[part 1 of 2: packages /MICROSAR/Dem_swc/DataTypes to /MICROSAR/Dem_swc/ComponentTypes]
AUTOSAR XML (schema 00046)
package /MICROSAR/Dem_swc/DataTypes
  23 x impl type:
    Dem_EventIdType: range raw 1..65535, implementation-data-type=uint16
    Dem_RatioIdType: range raw 1..65535, implementation-data-type=uint16
    Dem_DTCStatusMaskType: range raw 0..255, implementation-data-type=uint8
    Dem_OperationCycleIdType: range raw 0..255, implementation-data-type=uint8
    Dem_DTCGroupType: range raw 0..16777215, implementation-data-type=uint32
    Dem_EventStatusType:
      compu {0=DEM_EVENT_STATUS_PASSED, 1=DEM_EVENT_STATUS_FAILED, 2=DEM_EVENT_STATUS_PREPASSED, 3=DEM_EVENT_STATUS_PREFAILED, 4=DEM_EVENT_STATUS_FDC_THRESHOLD_REACHED, 5=DEM_EVENT_STATUS_PASSED_CONDITIONS_NOT_FULFILLED, 6=DEM_EVENT_STATUS_FAILED_CONDITIONS_NOT_FULFILLED, 7=DEM_EVENT_STATUS_PREPASSED_CONDITIONS_NOT_FULFILLED, 8=DEM_EVENT_STATUS_PREFAILED_CONDITIONS_NOT_FULFILLED}
      range raw 0..255
      implementation-data-type=uint8
    Dem_InitMonitorReasonType: compu {1=DEM_INIT_MONITOR_CLEAR, 2=DEM_INIT_MONITOR_RESTART, 3=DEM_INIT_MONITOR_REENABLED, 4=DEM_INIT_MONITOR_STORAGE_REENABLED}, range raw 0..255, implementation-data-type=uint8
    Dem_DTCOriginType:
      compu {1=DEM_DTC_ORIGIN_PRIMARY_MEMORY, 2=DEM_DTC_ORIGIN_MIRROR_MEMORY, 3=DEM_DTC_ORIGIN_PERMANENT_MEMORY, 4=DEM_DTC_ORIGIN_OBD_RELEVANT_MEMORY, 5=DEM_DTC_ORIGIN_SECONDARY_MEMORY, 5=DEM_DTC_ORIGIN_USERDEFINED_MEMORY_10, 5=DEM_DTC_ORIGIN_USERDEFINED_MEMORY_11, 5=DEM_DTC_ORIGIN_USERDEFINED_MEMORY_12, 5=DEM_DTC_ORIGIN_USERDEFINED_MEMORY_13, 5=DEM_DTC_ORIGIN_USERDEFINED_MEMORY_14, 5=DEM_DTC_ORIGIN_USERDEFINED_MEMORY_15, 5=DEM_DTC_ORIGIN_USERDEFINED_MEMORY_16, 5=DEM_DTC_ORIGIN_USERDEFINED_MEMORY_17, 5=DEM_DTC_ORIGIN_USERDEFINED_MEMORY_18, 5=DEM_DTC_ORIGIN_USERDEFINED_MEMORY_19, 5=DEM_DTC_ORIGIN_USERDEFINED_MEMORY_1A, 5=DEM_DTC_ORIGIN_USERDEFINED_MEMORY_1B, 5=DEM_DTC_ORIGIN_USERDEFINED_MEMORY_1C, 5=DEM_DTC_ORIGIN_USERDEFINED_MEMORY_1D, 5=DEM_DTC_ORIGIN_USERDEFINED_MEMORY_1E, 5=DEM_DTC_ORIGIN_USERDEFINED_MEMORY_1F, 5=DEM_DTC_ORIGIN_USERDEFINED_MEMORY_20, 5=DEM_DTC_ORIGIN_USERDEFINED_MEMORY_21, 5=DEM_DTC_ORIGIN_USERDEFINED_MEMORY_22, 5=DEM_DTC_ORIGIN_USERDEFINED_MEMORY_23, 5=DEM_DTC_ORIGIN_USERDEFINED_MEMORY_24, 5=DEM_DTC_ORIGIN_USERDEFINED_MEMORY_25, 5=DEM_DTC_ORIGIN_USERDEFINED_MEMORY_26, 5=DEM_DTC_ORIGIN_USERDEFINED_MEMORY_27, 5=DEM_DTC_ORIGIN_USERDEFINED_MEMORY_28, 5=DEM_DTC_ORIGIN_USERDEFINED_MEMORY_29, 5=DEM_DTC_ORIGIN_USERDEFINED_MEMORY_2A, 5=DEM_DTC_ORIGIN_USERDEFINED_MEMORY_2B, 5=DEM_DTC_ORIGIN_USERDEFINED_MEMORY_2C, 5=DEM_DTC_ORIGIN_USERDEFINED_MEMORY_2D, 5=DEM_DTC_ORIGIN_USERDEFINED_MEMORY_2E, 5=DEM_DTC_ORIGIN_USERDEFINED_MEMORY_2F, 5=DEM_DTC_ORIGIN_USERDEFINED_MEMORY_30, 5=DEM_DTC_ORIGIN_USERDEFINED_MEMORY_31, 5=DEM_DTC_ORIGIN_USERDEFINED_MEMORY_32, 5=DEM_DTC_ORIGIN_USERDEFINED_MEMORY_33, 5=DEM_DTC_ORIGIN_USERDEFINED_MEMORY_34, 5=DEM_DTC_ORIGIN_USERDEFINED_MEMORY_35, 5=DEM_DTC_ORIGIN_USERDEFINED_MEMORY_36, 5=DEM_DTC_ORIGIN_USERDEFINED_MEMORY_37, 5=DEM_DTC_ORIGIN_USERDEFINED_MEMORY_38, 5=DEM_DTC_ORIGIN_USERDEFINED_MEMORY_39, 5=DEM_DTC_ORIGIN_USERDEFINED_MEMORY_3A, 5=DEM_DTC_ORIGIN_USERDEFINED_MEMORY_3B, 5=DEM_DTC_ORIGIN_USERDEFINED_MEMORY_3C, 5=DEM_DTC_ORIGIN_USERDEFINED_MEMORY_3D, 5=DEM_DTC_ORIGIN_USERDEFINED_MEMORY_3E, 5=DEM_DTC_ORIGIN_USERDEFINED_MEMORY_3F, 5=DEM_DTC_ORIGIN_USERDEFINED_MEMORY_40, 5=DEM_DTC_ORIGIN_USERDEFINED_MEMORY_41, 5=DEM_DTC_ORIGIN_USERDEFINED_MEMORY_42, 5=DEM_DTC_ORIGIN_USERDEFINED_MEMORY_43, 5=DEM_DTC_ORIGIN_USERDEFINED_MEMORY_44, 5=DEM_DTC_ORIGIN_USERDEFINED_MEMORY_45, 5=DEM_DTC_ORIGIN_USERDEFINED_MEMORY_46, 5=DEM_DTC_ORIGIN_USERDEFINED_MEMORY_47, 5=DEM_DTC_ORIGIN_USERDEFINED_MEMORY_48, 5=DEM_DTC_ORIGIN_USERDEFINED_MEMORY_49, 5=DEM_DTC_ORIGIN_USERDEFINED_MEMORY_4A, 5=DEM_DTC_ORIGIN_USERDEFINED_MEMORY_4B, 5=DEM_DTC_ORIGIN_USERDEFINED_MEMORY_4C, 5=DEM_DTC_ORIGIN_USERDEFINED_MEMORY_4D, 5=DEM_DTC_ORIGIN_USERDEFINED_MEMORY_4E, 5=DEM_DTC_ORIGIN_USERDEFINED_MEMORY_4F, 5=DEM_DTC_ORIGIN_USERDEFINED_MEMORY_50, 5=DEM_DTC_ORIGIN_USERDEFINED_MEMORY_51, 5=DEM_DTC_ORIGIN_USERDEFINED_MEMORY_52, 5=DEM_DTC_ORIGIN_USERDEFINED_MEMORY_53, 5=DEM_DTC_ORIGIN_USERDEFINED_MEMORY_54, 5=DEM_DTC_ORIGIN_USERDEFINED_MEMORY_55, 5=DEM_DTC_ORIGIN_USERDEFINED_MEMORY_56, 5=DEM_DTC_ORIGIN_USERDEFINED_MEMORY_57, 5=DEM_DTC_ORIGIN_USERDEFINED_MEMORY_58, 5=DEM_DTC_ORIGIN_USERDEFINED_MEMORY_59, 5=DEM_DTC_ORIGIN_USERDEFINED_MEMORY_5A, 5=DEM_DTC_ORIGIN_USERDEFINED_MEMORY_5B, 5=DEM_DTC_ORIGIN_USERDEFINED_MEMORY_5C, 5=DEM_DTC_ORIGIN_USERDEFINED_MEMORY_5D, 5=DEM_DTC_ORIGIN_USERDEFINED_MEMORY_5E, 5=DEM_DTC_ORIGIN_USERDEFINED_MEMORY_5F, 5=DEM_DTC_ORIGIN_USERDEFINED_MEMORY_60, 5=DEM_DTC_ORIGIN_USERDEFINED_MEMORY_61, 5=DEM_DTC_ORIGIN_USERDEFINED_MEMORY_62, 5=DEM_DTC_ORIGIN_USERDEFINED_MEMORY_63, 5=DEM_DTC_ORIGIN_USERDEFINED_MEMORY_64, 5=DEM_DTC_ORIGIN_USERDEFINED_MEMORY_65, 5=DEM_DTC_ORIGIN_USERDEFINED_MEMORY_66, 5=DEM_DTC_ORIGIN_USERDEFINED_MEMORY_67, 5=DEM_DTC_ORIGIN_USERDEFINED_MEMORY_68, 5=DEM_DTC_ORIGIN_USERDEFINED_MEMORY_69, 5=DEM_DTC_ORIGIN_USERDEFINED_MEMORY_6A, 5=DEM_DTC_ORIGIN_USERDEFINED_MEMORY_6B, 5=DEM_DTC_ORIGIN_USERDEFINED_MEMORY_6C, 5=DEM_DTC_ORIGIN_USERDEFINED_MEMORY_6D, 5=DEM_DTC_ORIGIN_USERDEFINED_MEMORY_6E, 5=DEM_DTC_ORIGIN_USERDEFINED_MEMORY_6F, 5=DEM_DTC_ORIGIN_USERDEFINED_MEMORY_70, 5=DEM_DTC_ORIGIN_USERDEFINED_MEMORY_71, 5=DEM_DTC_ORIGIN_USERDEFINED_MEMORY_72, 5=DEM_DTC_ORIGIN_USERDEFINED_MEMORY_73, 5=DEM_DTC_ORIGIN_USERDEFINED_MEMORY_74, 5=DEM_DTC_ORIGIN_USERDEFINED_MEMORY_75, 5=DEM_DTC_ORIGIN_USERDEFINED_MEMORY_76, 5=DEM_DTC_ORIGIN_USERDEFINED_MEMORY_77, 5=DEM_DTC_ORIGIN_USERDEFINED_MEMORY_78, 5=DEM_DTC_ORIGIN_USERDEFINED_MEMORY_79, 5=DEM_DTC_ORIGIN_USERDEFINED_MEMORY_7A, 5=DEM_DTC_ORIGIN_USERDEFINED_MEMORY_7B, 5=DEM_DTC_ORIGIN_USERDEFINED_MEMORY_7C, 5=DEM_DTC_ORIGIN_USERDEFINED_MEMORY_7D, 5=DEM_DTC_ORIGIN_USERDEFINED_MEMORY_7E, 5=DEM_DTC_ORIGIN_USERDEFINED_MEMORY_7F, 5=DEM_DTC_ORIGIN_USERDEFINED_MEMORY_80, 5=DEM_DTC_ORIGIN_USERDEFINED_MEMORY_81, 5=DEM_DTC_ORIGIN_USERDEFINED_MEMORY_82, 5=DEM_DTC_ORIGIN_USERDEFINED_MEMORY_83, 5=DEM_DTC_ORIGIN_USERDEFINED_MEMORY_84, 5=DEM_DTC_ORIGIN_USERDEFINED_MEMORY_85, 5=DEM_DTC_ORIGIN_USERDEFINED_MEMORY_86, 5=DEM_DTC_ORIGIN_USERDEFINED_MEMORY_87, 5=DEM_DTC_ORIGIN_USERDEFINED_MEMORY_88, 5=DEM_DTC_ORIGIN_USERDEFINED_MEMORY_89, 5=DEM_DTC_ORIGIN_USERDEFINED_MEMORY_8A, 5=DEM_DTC_ORIGIN_USERDEFINED_MEMORY_8B, 5=DEM_DTC_ORIGIN_USERDEFINED_MEMORY_8C, 5=DEM_DTC_ORIGIN_USERDEFINED_MEMORY_8D, 5=DEM_DTC_ORIGIN_USERDEFINED_MEMORY_8E, 5=DEM_DTC_ORIGIN_USERDEFINED_MEMORY_8F, 5=DEM_DTC_ORIGIN_USERDEFINED_MEMORY_90, 5=DEM_DTC_ORIGIN_USERDEFINED_MEMORY_91, 5=DEM_DTC_ORIGIN_USERDEFINED_MEMORY_92, 5=DEM_DTC_ORIGIN_USERDEFINED_MEMORY_93, 5=DEM_DTC_ORIGIN_USERDEFINED_MEMORY_94, 5=DEM_DTC_ORIGIN_USERDEFINED_MEMORY_95, 5=DEM_DTC_ORIGIN_USERDEFINED_MEMORY_96, 5=DEM_DTC_ORIGIN_USERDEFINED_MEMORY_97, 5=DEM_DTC_ORIGIN_USERDEFINED_MEMORY_98, 5=DEM_DTC_ORIGIN_USERDEFINED_MEMORY_99, 5=DEM_DTC_ORIGIN_USERDEFINED_MEMORY_9A, 5=DEM_DTC_ORIGIN_USERDEFINED_MEMORY_9B, 5=DEM_DTC_ORIGIN_USERDEFINED_MEMORY_9C, 5=DEM_DTC_ORIGIN_USERDEFINED_MEMORY_9D, 5=DEM_DTC_ORIGIN_USERDEFINED_MEMORY_9E, 5=DEM_DTC_ORIGIN_USERDEFINED_MEMORY_9F, 5=DEM_DTC_ORIGIN_USERDEFINED_MEMORY_A0, 5=DEM_DTC_ORIGIN_USERDEFINED_MEMORY_A1, 5=DEM_DTC_ORIGIN_USERDEFINED_MEMORY_A2, 5=DEM_DTC_ORIGIN_USERDEFINED_MEMORY_A3, 5=DEM_DTC_ORIGIN_USERDEFINED_MEMORY_A4, 5=DEM_DTC_ORIGIN_USERDEFINED_MEMORY_A5, 5=DEM_DTC_ORIGIN_USERDEFINED_MEMORY_A6, 5=DEM_DTC_ORIGIN_USERDEFINED_MEMORY_A7, 5=DEM_DTC_ORIGIN_USERDEFINED_MEMORY_A8, 5=DEM_DTC_ORIGIN_USERDEFINED_MEMORY_A9, 5=DEM_DTC_ORIGIN_USERDEFINED_MEMORY_AA, 5=DEM_DTC_ORIGIN_USERDEFINED_MEMORY_AB, 5=DEM_DTC_ORIGIN_USERDEFINED_MEMORY_AC, 5=DEM_DTC_ORIGIN_USERDEFINED_MEMORY_AD, 5=DEM_DTC_ORIGIN_USERDEFINED_MEMORY_AE, 5=DEM_DTC_ORIGIN_USERDEFINED_MEMORY_AF, 5=DEM_DTC_ORIGIN_USERDEFINED_MEMORY_B0, 5=DEM_DTC_ORIGIN_USERDEFINED_MEMORY_B1, 5=DEM_DTC_ORIGIN_USERDEFINED_MEMORY_B2, 5=DEM_DTC_ORIGIN_USERDEFINED_MEMORY_B3, 5=DEM_DTC_ORIGIN_USERDEFINED_MEMORY_B4, 5=DEM_DTC_ORIGIN_USERDEFINED_MEMORY_B5, 5=DEM_DTC_ORIGIN_USERDEFINED_MEMORY_B6, 5=DEM_DTC_ORIGIN_USERDEFINED_MEMORY_B7, 5=DEM_DTC_ORIGIN_USERDEFINED_MEMORY_B8, 5=DEM_DTC_ORIGIN_USERDEFINED_MEMORY_B9, 5=DEM_DTC_ORIGIN_USERDEFINED_MEMORY_BA, 5=DEM_DTC_ORIGIN_USERDEFINED_MEMORY_BB, 5=DEM_DTC_ORIGIN_USERDEFINED_MEMORY_BC, 5=DEM_DTC_ORIGIN_USERDEFINED_MEMORY_BD, 5=DEM_DTC_ORIGIN_USERDEFINED_MEMORY_BE, 5=DEM_DTC_ORIGIN_USERDEFINED_MEMORY_BF, 5=DEM_DTC_ORIGIN_USERDEFINED_MEMORY_C0, 5=DEM_DTC_ORIGIN_USERDEFINED_MEMORY_C1, 5=DEM_DTC_ORIGIN_USERDEFINED_MEMORY_C2, 5=DEM_DTC_ORIGIN_USERDEFINED_MEMORY_C3, 5=DEM_DTC_ORIGIN_USERDEFINED_MEMORY_C4, 5=DEM_DTC_ORIGIN_USERDEFINED_MEMORY_C5, 5=DEM_DTC_ORIGIN_USERDEFINED_MEMORY_C6, 5=DEM_DTC_ORIGIN_USERDEFINED_MEMORY_C7, 5=DEM_DTC_ORIGIN_USERDEFINED_MEMORY_C8, 5=DEM_DTC_ORIGIN_USERDEFINED_MEMORY_C9, 5=DEM_DTC_ORIGIN_USERDEFINED_MEMORY_CA, 5=DEM_DTC_ORIGIN_USERDEFINED_MEMORY_CB, 5=DEM_DTC_ORIGIN_USERDEFINED_MEMORY_CC, 5=DEM_DTC_ORIGIN_USERDEFINED_MEMORY_CD, 5=DEM_DTC_ORIGIN_USERDEFINED_MEMORY_CE, 5=DEM_DTC_ORIGIN_USERDEFINED_MEMORY_CF, 5=DEM_DTC_ORIGIN_USERDEFINED_MEMORY_D0, 5=DEM_DTC_ORIGIN_USERDEFINED_MEMORY_D1, 5=DEM_DTC_ORIGIN_USERDEFINED_MEMORY_D2, 5=DEM_DTC_ORIGIN_USERDEFINED_MEMORY_D3, 5=DEM_DTC_ORIGIN_USERDEFINED_MEMORY_D4, 5=DEM_DTC_ORIGIN_USERDEFINED_MEMORY_D5, 5=DEM_DTC_ORIGIN_USERDEFINED_MEMORY_D6, 5=DEM_DTC_ORIGIN_USERDEFINED_MEMORY_D7, 5=DEM_DTC_ORIGIN_USERDEFINED_MEMORY_D8, 5=DEM_DTC_ORIGIN_USERDEFINED_MEMORY_D9, 5=DEM_DTC_ORIGIN_USERDEFINED_MEMORY_DA, 5=DEM_DTC_ORIGIN_USERDEFINED_MEMORY_DB, 5=DEM_DTC_ORIGIN_USERDEFINED_MEMORY_DC, 5=DEM_DTC_ORIGIN_USERDEFINED_MEMORY_DD, 5=DEM_DTC_ORIGIN_USERDEFINED_MEMORY_DE, 5=DEM_DTC_ORIGIN_USERDEFINED_MEMORY_DF, 5=DEM_DTC_ORIGIN_USERDEFINED_MEMORY_E0, 5=DEM_DTC_ORIGIN_USERDEFINED_MEMORY_E1, 5=DEM_DTC_ORIGIN_USERDEFINED_MEMORY_E2, 5=DEM_DTC_ORIGIN_USERDEFINED_MEMORY_E3, 5=DEM_DTC_ORIGIN_USERDEFINED_MEMORY_E4, 5=DEM_DTC_ORIGIN_USERDEFINED_MEMORY_E5, 5=DEM_DTC_ORIGIN_USERDEFINED_MEMORY_E6, 5=DEM_DTC_ORIGIN_USERDEFINED_MEMORY_E7, 5=DEM_DTC_ORIGIN_USERDEFINED_MEMORY_E8, 5=DEM_DTC_ORIGIN_USERDEFINED_MEMORY_E9, 5=DEM_DTC_ORIGIN_USERDEFINED_MEMORY_EA, 5=DEM_DTC_ORIGIN_USERDEFINED_MEMORY_EB, 5=DEM_DTC_ORIGIN_USERDEFINED_MEMORY_EC, 5=DEM_DTC_ORIGIN_USERDEFINED_MEMORY_ED, 5=DEM_DTC_ORIGIN_USERDEFINED_MEMORY_EE, 5=DEM_DTC_ORIGIN_USERDEFINED_MEMORY_EF, 5=DEM_DTC_ORIGIN_USERDEFINED_MEMORY_F0, 5=DEM_DTC_ORIGIN_USERDEFINED_MEMORY_F1, 5=DEM_DTC_ORIGIN_USERDEFINED_MEMORY_F2, 5=DEM_DTC_ORIGIN_USERDEFINED_MEMORY_F3, 5=DEM_DTC_ORIGIN_USERDEFINED_MEMORY_F4, 5=DEM_DTC_ORIGIN_USERDEFINED_MEMORY_F5, 5=DEM_DTC_ORIGIN_USERDEFINED_MEMORY_F6, 5=DEM_DTC_ORIGIN_USERDEFINED_MEMORY_F7, 5=DEM_DTC_ORIGIN_USERDEFINED_MEMORY_F8, 5=DEM_DTC_ORIGIN_USERDEFINED_MEMORY_F9, 5=DEM_DTC_ORIGIN_USERDEFINED_MEMORY_FA, 5=DEM_DTC_ORIGIN_USERDEFINED_MEMORY_FB, 5=DEM_DTC_ORIGIN_USERDEFINED_MEMORY_FC, 5=DEM_DTC_ORIGIN_USERDEFINED_MEMORY_FD, 5=DEM_DTC_ORIGIN_USERDEFINED_MEMORY_FE, 5=DEM_DTC_ORIGIN_USERDEFINED_MEMORY_FF}
      range raw 0..65535
      implementation-data-type=uint16
    Dem_DTCFormatType: compu {0=DEM_DTC_FORMAT_OBD, 1=DEM_DTC_FORMAT_UDS, 2=DEM_DTC_FORMAT_J1939}, range raw 0..255, implementation-data-type=uint8
    Dem_OperationCycleStateType: compu {0=DEM_CYCLE_STATE_START, 1=DEM_CYCLE_STATE_END}, range raw 0..255, implementation-data-type=uint8
    Dem_IndicatorStatusType: compu {0=DEM_INDICATOR_OFF, 1=DEM_INDICATOR_CONTINUOUS, 2=DEM_INDICATOR_BLINKING, 3=DEM_INDICATOR_BLINK_CONT, 4=DEM_INDICATOR_SLOW_FLASH, 5=DEM_INDICATOR_FAST_FLASH, 6=DEM_INDICATOR_ON_DEMAND, 7=DEM_INDICATOR_SHORT}, range raw 0..255, implementation-data-type=uint8
    Dem_DTCKindType: compu {1=DEM_DTC_KIND_ALL_DTCS, 2=DEM_DTC_KIND_EMISSION_REL_DTCS}, range raw 0..255, implementation-data-type=uint8
    Dem_IumprDenomCondIdType: compu {1=DEM_IUMPR_GENERAL_DENOMINATOR, 2=DEM_IUMPR_DEN_COND_COLDSTART, 3=DEM_IUMPR_DEN_COND_EVAP, 4=DEM_IUMPR_DEN_COND_500MI}, range raw 0..255, implementation-data-type=uint8
    Dem_IumprDenomCondStatusType: compu {0=DEM_IUMPR_DEN_STATUS_NOT_REACHED, 1=DEM_IUMPR_DEN_STATUS_REACHED, 2=DEM_IUMPR_DEN_STATUS_INHIBITED}, range raw 0..255, implementation-data-type=uint8
    Dem_DebounceResetStatusType: compu {0=DEM_DEBOUNCE_STATUS_FREEZE, 1=DEM_DEBOUNCE_STATUS_RESET}, range raw 0..255, implementation-data-type=uint8
    Dem_IumprReadinessGroupType:
      compu {0=DEM_IUMPR_BOOSTPRS, 1=DEM_IUMPR_CAT1, 2=DEM_IUMPR_CAT2, 3=DEM_IUMPR_EGR, 4=DEM_IUMPR_EGSENSOR, 5=DEM_IUMPR_EVAP, 6=DEM_IUMPR_NMHCCAT, 7=DEM_IUMPR_NOXADSORB, 8=DEM_IUMPR_NOXCAT, 9=DEM_IUMPR_OXS1, 10=DEM_IUMPR_OXS2, 11=DEM_IUMPR_PMFILTER, 12=DEM_IUMPR_PRIVATE, 13=DEM_IUMPR_SAIR, 14=DEM_IUMPR_SECOXS1, 15=DEM_IUMPR_SECOXS2, 16=DEM_IUMPR_FLSYS, 17=DEM_IUMPR_AFRI1, 18=DEM_IUMPR_AFRI2, 19=DEM_IUMPR_PF1, 20=DEM_IUMPR_PF2, 255=DEM_IUMPR_ALLGROUPS}
      range raw 0..255
      implementation-data-type=uint8
    Dem_DTRControlType: compu {0=DEM_DTR_CTL_NORMAL, 1=DEM_DTR_CTL_NO_MAX, 2=DEM_DTR_CTL_NO_MIN, 3=DEM_DTR_CTL_RESET, 4=DEM_DTR_CTL_INVISIBLE}, range raw 0..255, implementation-data-type=uint8
    Dem_DebouncingStateType:
      compu {mask 1: 1=DEM_TEMPORARILY_DEFECTIVE (Bit 0: Temporarily Defective (corresponds to 0 < FDC < 127)), mask 2: 2=DEM_FINALLY_DEFECTIVE (Bit 1: Finally Defective (corresponds to FDC = 127)), mask 4: 4=DEM_TEMPORARILY_HEALED (Bit 2: Temporarily healed (corresponds to -128 < FDC < 0)), mask 8: 8=DEM_TEST_COMPLETE (Bit 3: Test complete (corresponds to FDC = -128 or FDC = 127)), mask 16: 16=DEM_DTR_UPDATE (Bit 4: DTR Update (= Test complete && Debouncing complete && enable conditions / storage conditions fulfilled))}
      range raw 0..255
      implementation-data-type=uint8
    Dem_DTCSeverityType:
      compu {mask 255: 0=DEM_SEVERITY_NO_SEVERITY (DTC_NO_SEVERITY) (No severity information available), mask 31: 1=DEM_SEVERITY_WWHOBD_CLASS_NO_CLASS (DTC_CLASS) (No class information), mask 31: 2=DEM_SEVERITY_WWHOBD_CLASS_A (DTC_CLASS) (WWH-OBD Class A), mask 31: 4=DEM_SEVERITY_WWHOBD_CLASS_B1 (DTC_CLASS) (WWH-OBD Class B1), mask 31: 8=DEM_SEVERITY_WWHOBD_CLASS_B2 (DTC_CLASS) (WWH-OBD Class B2), mask 31: 16=DEM_SEVERITY_WWHOBD_CLASS_C (DTC_CLASS) (WWH-OBD Class C), mask 224: 32=DEM_SEVERITY_MAINTENANCE_ONLY (DTC_SEVERITY) (Maintenance required), mask 224: 64=DEM_SEVERITY_CHECK_AT_NEXT_HALT (DTC_SEVERITY) (Check at next halt), mask 224: 128=DEM_SEVERITY_CHECK_IMMEDIATELY (DTC_SEVERITY) (Check immediately)}
      range raw 0..255
      implementation-data-type=uint8
    Dem_UdsStatusByteType:
      compu {mask 1: 1=DEM_UDS_STATUS_TF (bit 0: TestFailed), mask 2: 2=DEM_UDS_STATUS_TFTOC (bit 1: TestFailedThisOperationCycle), mask 4: 4=DEM_UDS_STATUS_PDTC (bit 2: PendingDTC), mask 8: 8=DEM_UDS_STATUS_CDTC (bit 3: ConfirmedDTC), mask 16: 16=DEM_UDS_STATUS_TNCSLC (bit 4: TestNotCompletedSinceLastClear), mask 32: 32=DEM_UDS_STATUS_TFSLC (bit 5: TestFailedSinceLastClear), mask 64: 64=DEM_UDS_STATUS_TNCTOC (bit 6: TestNotCompletedThisOperationCycle), mask 128: 128=DEM_UDS_STATUS_WIR (bit 7: WarningIndicatorRequested)}
      range raw 0..255
      implementation-data-type=uint8
    Dem_MonitorStatusType: compu {mask 1: 1=DEM_MONITOR_STATUS_TF (bit 0: TestFailed), mask 2: 2=DEM_MONITOR_STATUS_TNCTOC (bit 1: TestNotCompletedThisOperationCycle)}, range raw 0..255, implementation-data-type=uint8
    Dem_MaxDataValueType: category=ARRAY, sw-calibration-access=READ-ONLY
      element Dem_MaxDataValueTypeElement: array-size=9, array-size-semantics=FIXED-SIZE, implementation-data-type=uint8
    DataArrayType_uint8_1: category=ARRAY, sw-calibration-access=READ-ONLY
      element DataArrayType_uint8_1Element: array-size=1, array-size-semantics=FIXED-SIZE, implementation-data-type=uint8
package /MICROSAR/Dem_swc/Interfaces
  29 x client server interface, all with is-service=true, service-kind=DIAGNOSTIC-EVENT-MANAGER:
    DemServices
      operation GetPostRunRequested: possible-error=DemServices/E_NOT_OK
        arg IsRequested: type=boolean, direction=OUT
      operation GetDTCStatusAvailabilityMask: possible-error=DemServices/E_NOT_OK
        arg ClientId: type=uint8, direction=IN
        arg DTCStatusMask: type=uint8, direction=OUT
      error E_NOT_OK: error-code=1
    CallbackGetFaultDetectCounter
      operation GetFaultDetectionCounter: possible-error=CallbackGetFaultDetectCounter/E_NOT_OK
        arg FaultDetectionCounter: type=sint8, direction=OUT
      error E_NOT_OK: error-code=1
    ClearDTC
      operation ClearDTC: possible-error=[ClearDTC/E_NOT_OK, DEM_CLEAR_FAILED, DEM_PENDING, DEM_CLEAR_BUSY, DEM_CLEAR_MEMORY_ERROR, DEM_WRONG_DTC, DEM_WRONG_DTCORIGIN]
      operation SelectDTC: possible-error=[ClearDTC/E_OK, ClearDTC/E_NOT_OK]
        arg DTC: type=uint32, direction=IN
        arg DTCFormat: type=Dem_DTCFormatType, direction=IN
        arg DTCOrigin: type=Dem_DTCOriginType, direction=IN
      8 x error:
        E_OK: error-code=0
        E_NOT_OK: error-code=1
        DEM_CLEAR_FAILED: error-code=7
        DEM_PENDING: error-code=4
        DEM_CLEAR_BUSY: error-code=5
        DEM_CLEAR_MEMORY_ERROR: error-code=6
        DEM_WRONG_DTC: error-code=8
        DEM_WRONG_DTCORIGIN: error-code=9
    EvMemOverflowIndication
      operation GetEventMemoryOverflow: possible-error=EvMemOverflowIndication/E_NOT_OK
        arg OverflowIndication: type=boolean, direction=OUT
      operation GetNumberOfEventMemoryEntries: possible-error=EvMemOverflowIndication/E_NOT_OK
        arg NumberOfEventMemoryEntries: type=uint8, direction=OUT
      error E_NOT_OK: error-code=1
    GeneralDiagnosticInfo
      11 x operation:
        GetEventUdsStatus: possible-error=GeneralDiagnosticInfo/E_NOT_OK
          arg EventId: type=Dem_EventIdType, direction=IN
          arg UDSStatusByte: type=Dem_UdsStatusByteType, direction=OUT
        GetEventStatus: possible-error=GeneralDiagnosticInfo/E_NOT_OK
          arg EventId: type=Dem_EventIdType, direction=IN
          arg UDSStatusByte: type=Dem_UdsStatusByteType, direction=OUT
        GetEventFailed: possible-error=GeneralDiagnosticInfo/E_NOT_OK
          arg EventId: type=Dem_EventIdType, direction=IN
          arg EventFailed: type=boolean, direction=OUT
        GetEventTested: possible-error=GeneralDiagnosticInfo/E_NOT_OK
          arg EventId: type=Dem_EventIdType, direction=IN
          arg EventTested: type=boolean, direction=OUT
        GetDTCOfEvent: possible-error=[GeneralDiagnosticInfo/E_NOT_OK, GeneralDiagnosticInfo/DEM_E_NO_DTC_AVAILABLE]
          arg EventId: type=Dem_EventIdType, direction=IN
          arg DTCFormat: type=Dem_DTCFormatType, direction=IN
          arg DTCOfEvent: type=uint32, direction=OUT
        GetFaultDetectionCounter: possible-error=[GeneralDiagnosticInfo/E_NOT_OK, GeneralDiagnosticInfo/DEM_E_NO_FDC_AVAILABLE]
          arg EventId: type=Dem_EventIdType, direction=IN
          arg FaultDetectionCounter: type=sint8, direction=OUT
        GetEventFreezeFrameDataEx: possible-error=[GeneralDiagnosticInfo/E_NOT_OK, GeneralDiagnosticInfo/DEM_BUFFER_TOO_SMALL, GeneralDiagnosticInfo/DEM_NO_SUCH_ELEMENT]
          5 x arg:
            EventId: type=Dem_EventIdType, direction=IN
            RecordNumber: type=uint8, direction=IN
            DataId: type=uint16, direction=IN
            DestBuffer: type=Dem_MaxDataValueType, direction=OUT
            BufSize: type=uint16, direction=INOUT
        GetEventExtendedDataRecordEx: possible-error=[GeneralDiagnosticInfo/E_NOT_OK, GeneralDiagnosticInfo/DEM_BUFFER_TOO_SMALL, GeneralDiagnosticInfo/DEM_NO_SUCH_ELEMENT]
          4 x arg:
            EventId: type=Dem_EventIdType, direction=IN
            RecordNumber: type=uint8, direction=IN
            DestBuffer: type=Dem_MaxDataValueType, direction=OUT
            BufSize: type=uint16, direction=INOUT
        GetEventEnableCondition: possible-error=GeneralDiagnosticInfo/E_NOT_OK
          arg EventId: type=Dem_EventIdType, direction=IN
          arg ConditionFullfilled: type=boolean, direction=OUT
        GetDebouncingOfEvent: possible-error=GeneralDiagnosticInfo/E_NOT_OK
          arg EventId: type=Dem_EventIdType, direction=IN
          arg DebouncingState: type=Dem_DebouncingStateType, direction=OUT
        GetMonitorStatus: possible-error=GeneralDiagnosticInfo/E_NOT_OK
          arg EventId: type=Dem_EventIdType, direction=IN
          arg MonitorStatus: type=Dem_MonitorStatusType, direction=OUT
      5 x error:
        E_NOT_OK: error-code=1
        DEM_E_NO_DTC_AVAILABLE: error-code=10
        DEM_E_NO_FDC_AVAILABLE: error-code=14
        DEM_BUFFER_TOO_SMALL: error-code=21
        DEM_NO_SUCH_ELEMENT: error-code=48
    OperationCycle
      operation GetOperationCycleState: possible-error=[OperationCycle/E_OK, OperationCycle/E_NOT_OK]
        arg CycleState: type=Dem_OperationCycleStateType, direction=OUT
      operation SetOperationCycleState: possible-error=[OperationCycle/E_OK, OperationCycle/E_NOT_OK]
        arg CycleState: type=Dem_OperationCycleStateType, direction=IN
      error E_OK: error-code=0
      error E_NOT_OK: error-code=1
    DiagnosticInfo
      11 x operation:
        GetEventUdsStatus: possible-error=DiagnosticInfo/E_NOT_OK
          arg UDSStatusByte: type=Dem_UdsStatusByteType, direction=OUT
        GetEventStatus: possible-error=DiagnosticInfo/E_NOT_OK
          arg UDSStatusByte: type=Dem_UdsStatusByteType, direction=OUT
        GetEventFailed: possible-error=DiagnosticInfo/E_NOT_OK
          arg EventFailed: type=boolean, direction=OUT
        GetEventTested: possible-error=DiagnosticInfo/E_NOT_OK
          arg EventTested: type=boolean, direction=OUT
        GetDTCOfEvent: possible-error=[DiagnosticInfo/E_NOT_OK, DiagnosticInfo/DEM_E_NO_DTC_AVAILABLE]
          arg DTCFormat: type=Dem_DTCFormatType, direction=IN
          arg DTCOfEvent: type=uint32, direction=OUT
        GetFaultDetectionCounter: possible-error=[DiagnosticInfo/E_NOT_OK, DiagnosticInfo/DEM_E_NO_FDC_AVAILABLE]
          arg FaultDetectionCounter: type=sint8, direction=OUT
        GetEventFreezeFrameDataEx: possible-error=[DiagnosticInfo/E_NOT_OK, DiagnosticInfo/DEM_BUFFER_TOO_SMALL, DiagnosticInfo/DEM_NO_SUCH_ELEMENT]
          4 x arg:
            RecordNumber: type=uint8, direction=IN
            DataId: type=uint16, direction=IN
            DestBuffer: type=Dem_MaxDataValueType, direction=OUT
            BufSize: type=uint16, direction=INOUT
        GetEventExtendedDataRecordEx: possible-error=[DiagnosticInfo/E_NOT_OK, DiagnosticInfo/DEM_BUFFER_TOO_SMALL, DiagnosticInfo/DEM_NO_SUCH_ELEMENT]
          arg RecordNumber: type=uint8, direction=IN
          arg DestBuffer: type=Dem_MaxDataValueType, direction=OUT
          arg BufSize: type=uint16, direction=INOUT
        GetEventEnableCondition: possible-error=DiagnosticInfo/E_NOT_OK
          arg ConditionFullfilled: type=boolean, direction=OUT
        GetDebouncingOfEvent: possible-error=DiagnosticInfo/E_NOT_OK
          arg DebouncingState: type=Dem_DebouncingStateType, direction=OUT
        GetMonitorStatus: possible-error=DiagnosticInfo/E_NOT_OK
          arg MonitorStatus: type=Dem_MonitorStatusType, direction=OUT
      5 x error:
        E_NOT_OK: error-code=1
        DEM_E_NO_DTC_AVAILABLE: error-code=10
        DEM_E_NO_FDC_AVAILABLE: error-code=14
        DEM_BUFFER_TOO_SMALL: error-code=21
        DEM_NO_SUCH_ELEMENT: error-code=48
    DiagnosticMonitor
      11 x operation:
        SetEventStatus: possible-error=DiagnosticMonitor/E_NOT_OK
          arg EventStatus: type=Dem_EventStatusType, direction=IN
        ResetEventStatus: possible-error=DiagnosticMonitor/E_NOT_OK
        ResetEventDebounceStatus: possible-error=DiagnosticMonitor/E_NOT_OK
          arg DebounceResetStatus: type=Dem_DebounceResetStatusType, direction=IN
        GetEventUdsStatus: possible-error=DiagnosticMonitor/E_NOT_OK
          arg UDSStatusByte: type=Dem_UdsStatusByteType, direction=OUT
        GetEventStatus: possible-error=DiagnosticMonitor/E_NOT_OK
          arg UDSStatusByte: type=Dem_UdsStatusByteType, direction=OUT
        GetEventFailed: possible-error=DiagnosticMonitor/E_NOT_OK
          arg EventFailed: type=boolean, direction=OUT
        GetEventTested: possible-error=DiagnosticMonitor/E_NOT_OK
          arg EventTested: type=boolean, direction=OUT
        GetDTCOfEvent: possible-error=[DiagnosticMonitor/E_NOT_OK, DiagnosticMonitor/DEM_E_NO_DTC_AVAILABLE]
          arg DTCFormat: type=Dem_DTCFormatType, direction=IN
          arg DTCOfEvent: type=uint32, direction=OUT
        GetFaultDetectionCounter: possible-error=[DiagnosticMonitor/E_NOT_OK, DiagnosticMonitor/DEM_E_NO_FDC_AVAILABLE]
          arg FaultDetectionCounter: type=sint8, direction=OUT
        GetEventFreezeFrameDataEx: possible-error=[DiagnosticMonitor/E_NOT_OK, DiagnosticMonitor/DEM_BUFFER_TOO_SMALL, DiagnosticMonitor/DEM_NO_SUCH_ELEMENT]
          4 x arg:
            RecordNumber: type=uint8, direction=IN
            DataId: type=uint16, direction=IN
            DestBuffer: type=Dem_MaxDataValueType, direction=OUT
            BufSize: type=uint16, direction=INOUT
        GetEventExtendedDataRecordEx: possible-error=[DiagnosticMonitor/E_NOT_OK, DiagnosticMonitor/DEM_BUFFER_TOO_SMALL, DiagnosticMonitor/DEM_NO_SUCH_ELEMENT]
          arg RecordNumber: type=uint8, direction=IN
          arg DestBuffer: type=Dem_MaxDataValueType, direction=OUT
          arg BufSize: type=uint16, direction=INOUT
      5 x error:
        E_NOT_OK: error-code=1
        DEM_E_NO_DTC_AVAILABLE: error-code=10
        DEM_E_NO_FDC_AVAILABLE: error-code=14
        DEM_BUFFER_TOO_SMALL: error-code=21
        DEM_NO_SUCH_ELEMENT: error-code=48
    CSDataServices_UncompletedTestCounters_Driving_Cycles_Since_Last_Completed
      operation ReadData: possible-error=CSDataServices_UncompletedTestCounters_Driving_Cycles_Since_Last_Completed/E_NOT_OK
        arg Data: type=DataArrayType_uint8_1, direction=OUT
      error E_NOT_OK: error-code=1
    CSDataServices_DID_0x10d_Valve_Voltage_RL
      operation ReadData: possible-error=CSDataServices_DID_0x10d_Valve_Voltage_RL/E_NOT_OK
        arg Data: type=DataArrayType_uint8_1, direction=OUT
      error E_NOT_OK: error-code=1
    CSDataServices_DID_0x10a_Wheel_Voltage_RL
      operation ReadData: possible-error=CSDataServices_DID_0x10a_Wheel_Voltage_RL/E_NOT_OK
        arg Data: type=DataArrayType_uint8_1, direction=OUT
      error E_NOT_OK: error-code=1
    CSDataServices_DID_0x107_Voltage_ECU
      operation ReadData: possible-error=CSDataServices_DID_0x107_Voltage_ECU/E_NOT_OK
        arg Data: type=DataArrayType_uint8_1, direction=OUT
      error E_NOT_OK: error-code=1
    CSDataServices_DID_0x10d_Valve_Voltage_RR
      operation ReadData: possible-error=CSDataServices_DID_0x10d_Valve_Voltage_RR/E_NOT_OK
        arg Data: type=DataArrayType_uint8_1, direction=OUT
      error E_NOT_OK: error-code=1
    CSDataServices_DTCAgingCounter_Driving_Cycles_Since_Last_Failed
      operation ReadData: possible-error=CSDataServices_DTCAgingCounter_Driving_Cycles_Since_Last_Failed/E_NOT_OK
        arg Data: type=DataArrayType_uint8_1, direction=OUT
      error E_NOT_OK: error-code=1
    CSDataServices_DID_0x10d_Valve_Status_FR
      operation ReadData: possible-error=CSDataServices_DID_0x10d_Valve_Status_FR/E_NOT_OK
        arg Data: type=DataArrayType_uint8_1, direction=OUT
      error E_NOT_OK: error-code=1
    CSDataServices_DID_0x10a_Wheel_Voltage_RR
      operation ReadData: possible-error=CSDataServices_DID_0x10a_Wheel_Voltage_RR/E_NOT_OK
        arg Data: type=DataArrayType_uint8_1, direction=OUT
      error E_NOT_OK: error-code=1
    CSDataServices_DID_0x10a_Wheel_Voltage_FR
      operation ReadData: possible-error=CSDataServices_DID_0x10a_Wheel_Voltage_FR/E_NOT_OK
        arg Data: type=DataArrayType_uint8_1, direction=OUT
      error E_NOT_OK: error-code=1
    CSDataServices_DID_0x10a_Wheel_Voltage_FL
      operation ReadData: possible-error=CSDataServices_DID_0x10a_Wheel_Voltage_FL/E_NOT_OK
        arg Data: type=DataArrayType_uint8_1, direction=OUT
      error E_NOT_OK: error-code=1
    CSDataServices_DID_0x10d_Valve_Status_RR
      operation ReadData: possible-error=CSDataServices_DID_0x10d_Valve_Status_RR/E_NOT_OK
        arg Data: type=DataArrayType_uint8_1, direction=OUT
      error E_NOT_OK: error-code=1
    CSDataServices_DID_0x10a_Wheel_Speed_RL
      operation ReadData: possible-error=CSDataServices_DID_0x10a_Wheel_Speed_RL/E_NOT_OK
        arg Data: type=DataArrayType_uint8_1, direction=OUT
      error E_NOT_OK: error-code=1
    CSDataServices_DID_0x10a_Wheel_Speed_RR
      operation ReadData: possible-error=CSDataServices_DID_0x10a_Wheel_Speed_RR/E_NOT_OK
        arg Data: type=DataArrayType_uint8_1, direction=OUT
      error E_NOT_OK: error-code=1
    CSDataServices_DID_0x10a_Wheel_Speed_FL
      operation ReadData: possible-error=CSDataServices_DID_0x10a_Wheel_Speed_FL/E_NOT_OK
        arg Data: type=DataArrayType_uint8_1, direction=OUT
      error E_NOT_OK: error-code=1
    CSDataServices_DID_0x10d_Valve_Status_FL
      operation ReadData: possible-error=CSDataServices_DID_0x10d_Valve_Status_FL/E_NOT_OK
        arg Data: type=DataArrayType_uint8_1, direction=OUT
      error E_NOT_OK: error-code=1
    CSDataServices_DID_0x10a_Direction_of_rotation
      operation ReadData: possible-error=CSDataServices_DID_0x10a_Direction_of_rotation/E_NOT_OK
        arg Data: type=DataArrayType_uint8_1, direction=OUT
      error E_NOT_OK: error-code=1
    CSDataServices_DID_0x10d_Valve_Voltage_FL
      operation ReadData: possible-error=CSDataServices_DID_0x10d_Valve_Voltage_FL/E_NOT_OK
        arg Data: type=DataArrayType_uint8_1, direction=OUT
      error E_NOT_OK: error-code=1
    CSDataServices_DID_0x10a_Wheel_Speed_FR
      operation ReadData: possible-error=CSDataServices_DID_0x10a_Wheel_Speed_FR/E_NOT_OK
        arg Data: type=DataArrayType_uint8_1, direction=OUT
      error E_NOT_OK: error-code=1
    CSDataServices_DID_0x10d_Valve_Voltage_FR
      operation ReadData: possible-error=CSDataServices_DID_0x10d_Valve_Voltage_FR/E_NOT_OK
        arg Data: type=DataArrayType_uint8_1, direction=OUT
      error E_NOT_OK: error-code=1
    CSDataServices_OccurrenceCounter_Driving_Cycles_Since_Test_Failed
      operation ReadData: possible-error=CSDataServices_OccurrenceCounter_Driving_Cycles_Since_Test_Failed/E_NOT_OK
        arg Data: type=DataArrayType_uint8_1, direction=OUT
      error E_NOT_OK: error-code=1
    CSDataServices_DID_0x10d_Valve_Status_RL
      operation ReadData: possible-error=CSDataServices_DID_0x10d_Valve_Status_RL/E_NOT_OK
        arg Data: type=DataArrayType_uint8_1, direction=OUT
      error E_NOT_OK: error-code=1
package /MICROSAR/Dem_swc/ComponentTypes
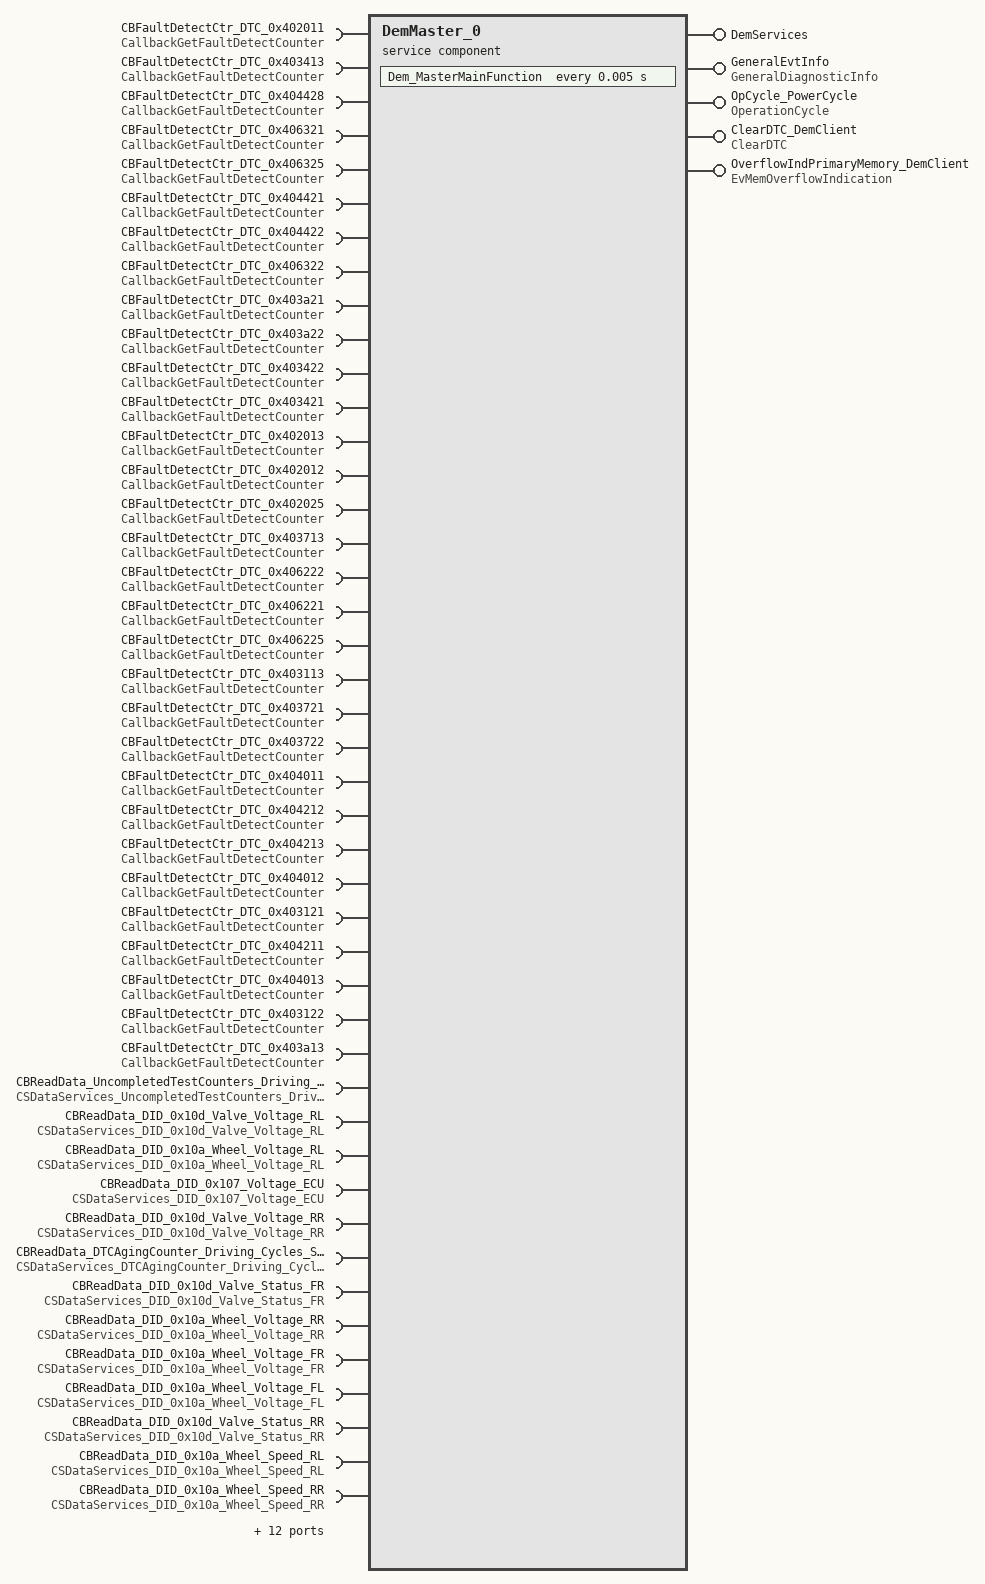
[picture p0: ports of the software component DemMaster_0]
  service sw component type DemMaster_0: category=SERVICE_COMPONENT
    provide port DemServices: provided-interface=DemServices
    require port CBFaultDetectCtr_DTC_0x402011: required-interface=CallbackGetFaultDetectCounter
    4 x provide port:
      GeneralEvtInfo: provided-interface=GeneralDiagnosticInfo
      OpCycle_PowerCycle: provided-interface=OperationCycle
      ClearDTC_DemClient: provided-interface=ClearDTC
      OverflowIndPrimaryMemory_DemClient: provided-interface=EvMemOverflowIndication
    55 x require port:
      CBFaultDetectCtr_DTC_0x403413: required-interface=CallbackGetFaultDetectCounter
      CBFaultDetectCtr_DTC_0x404428: required-interface=CallbackGetFaultDetectCounter
      CBFaultDetectCtr_DTC_0x406321: required-interface=CallbackGetFaultDetectCounter
      CBFaultDetectCtr_DTC_0x406325: required-interface=CallbackGetFaultDetectCounter
      CBFaultDetectCtr_DTC_0x404421: required-interface=CallbackGetFaultDetectCounter
      CBFaultDetectCtr_DTC_0x404422: required-interface=CallbackGetFaultDetectCounter
      CBFaultDetectCtr_DTC_0x406322: required-interface=CallbackGetFaultDetectCounter
      CBFaultDetectCtr_DTC_0x403a21: required-interface=CallbackGetFaultDetectCounter
      CBFaultDetectCtr_DTC_0x403a22: required-interface=CallbackGetFaultDetectCounter
      CBFaultDetectCtr_DTC_0x403422: required-interface=CallbackGetFaultDetectCounter
      CBFaultDetectCtr_DTC_0x403421: required-interface=CallbackGetFaultDetectCounter
      CBFaultDetectCtr_DTC_0x402013: required-interface=CallbackGetFaultDetectCounter
      CBFaultDetectCtr_DTC_0x402012: required-interface=CallbackGetFaultDetectCounter
      CBFaultDetectCtr_DTC_0x402025: required-interface=CallbackGetFaultDetectCounter
      CBFaultDetectCtr_DTC_0x403713: required-interface=CallbackGetFaultDetectCounter
      CBFaultDetectCtr_DTC_0x406222: required-interface=CallbackGetFaultDetectCounter
      CBFaultDetectCtr_DTC_0x406221: required-interface=CallbackGetFaultDetectCounter
      CBFaultDetectCtr_DTC_0x406225: required-interface=CallbackGetFaultDetectCounter
      CBFaultDetectCtr_DTC_0x403113: required-interface=CallbackGetFaultDetectCounter
      CBFaultDetectCtr_DTC_0x403721: required-interface=CallbackGetFaultDetectCounter
      CBFaultDetectCtr_DTC_0x403722: required-interface=CallbackGetFaultDetectCounter
      CBFaultDetectCtr_DTC_0x404011: required-interface=CallbackGetFaultDetectCounter
      CBFaultDetectCtr_DTC_0x404212: required-interface=CallbackGetFaultDetectCounter
      CBFaultDetectCtr_DTC_0x404213: required-interface=CallbackGetFaultDetectCounter
      CBFaultDetectCtr_DTC_0x404012: required-interface=CallbackGetFaultDetectCounter
      CBFaultDetectCtr_DTC_0x403121: required-interface=CallbackGetFaultDetectCounter
      CBFaultDetectCtr_DTC_0x404211: required-interface=CallbackGetFaultDetectCounter
      CBFaultDetectCtr_DTC_0x404013: required-interface=CallbackGetFaultDetectCounter
      CBFaultDetectCtr_DTC_0x403122: required-interface=CallbackGetFaultDetectCounter
      CBFaultDetectCtr_DTC_0x403a13: required-interface=CallbackGetFaultDetectCounter
      CBReadData_UncompletedTestCounters_Driving_Cycles_Since_Last_Completed: required-interface=CSDataServices_UncompletedTestCounters_Driving_Cycles_Since_Last_Completed
      CBReadData_DID_0x10d_Valve_Voltage_RL: required-interface=CSDataServices_DID_0x10d_Valve_Voltage_RL
      CBReadData_DID_0x10a_Wheel_Voltage_RL: required-interface=CSDataServices_DID_0x10a_Wheel_Voltage_RL
      CBReadData_DID_0x107_Voltage_ECU: required-interface=CSDataServices_DID_0x107_Voltage_ECU
      CBReadData_DID_0x10d_Valve_Voltage_RR: required-interface=CSDataServices_DID_0x10d_Valve_Voltage_RR
      CBReadData_DTCAgingCounter_Driving_Cycles_Since_Last_Failed: required-interface=CSDataServices_DTCAgingCounter_Driving_Cycles_Since_Last_Failed
      CBReadData_DID_0x10d_Valve_Status_FR: required-interface=CSDataServices_DID_0x10d_Valve_Status_FR
      CBReadData_DID_0x10a_Wheel_Voltage_RR: required-interface=CSDataServices_DID_0x10a_Wheel_Voltage_RR
      CBReadData_DID_0x10a_Wheel_Voltage_FR: required-interface=CSDataServices_DID_0x10a_Wheel_Voltage_FR
      CBReadData_DID_0x10a_Wheel_Voltage_FL: required-interface=CSDataServices_DID_0x10a_Wheel_Voltage_FL
      CBReadData_DID_0x10d_Valve_Status_RR: required-interface=CSDataServices_DID_0x10d_Valve_Status_RR
      CBReadData_DID_0x10a_Wheel_Speed_RL: required-interface=CSDataServices_DID_0x10a_Wheel_Speed_RL
      CBReadData_DID_0x10a_Wheel_Speed_RR: required-interface=CSDataServices_DID_0x10a_Wheel_Speed_RR
      CBReadData_DID_0x10a_Wheel_Speed_FL: required-interface=CSDataServices_DID_0x10a_Wheel_Speed_FL
      CBReadData_DID_0x10d_Valve_Status_FL: required-interface=CSDataServices_DID_0x10d_Valve_Status_FL
      CBReadData_DID_0x10a_Direction_of_rotation: required-interface=CSDataServices_DID_0x10a_Direction_of_rotation
      CBReadData_DID_0x10d_Valve_Voltage_FL: required-interface=CSDataServices_DID_0x10d_Valve_Voltage_FL
      CBReadData_DID_0x10a_Wheel_Speed_FR: required-interface=CSDataServices_DID_0x10a_Wheel_Speed_FR
      CBReadData_DID_0x10d_Valve_Voltage_FR: required-interface=CSDataServices_DID_0x10d_Valve_Voltage_FR
      CBReadData_OccurrenceCounter_Driving_Cycles_Since_Test_Failed: required-interface=CSDataServices_OccurrenceCounter_Driving_Cycles_Since_Test_Failed
      CBReadData_DID_0x10d_Valve_Status_RL: required-interface=CSDataServices_DID_0x10d_Valve_Status_RL
      CBFaultDetectCtr_DTC_0x401003: required-interface=CallbackGetFaultDetectCounter
      CBFaultDetectCtr_DTC_0x401001: required-interface=CallbackGetFaultDetectCounter
      CBFaultDetectCtr_DTC_0x402001: required-interface=CallbackGetFaultDetectCounter
      CBFaultDetectCtr_DTC_0x403001: required-interface=CallbackGetFaultDetectCounter
    behavior DemMaster_0InternalBehavior: handle-termination-and-restart=NO-SUPPORT, included-data-type-set=data-type=[Dem_EventIdType, Dem_RatioIdType, Dem_EventStatusType, Dem_UdsStatusByteType, Dem_DTCFormatType, Dem_InitMonitorReasonType, Dem_OperationCycleStateType, Dem_DTCStatusMaskType, Dem_IndicatorStatusType, Dem_MaxDataValueType, Dem_DTCKindType, Dem_DTCGroupType, Dem_IumprDenomCondIdType, Dem_IumprDenomCondStatusType, Dem_DebounceResetStatusType, Dem_DebouncingStateType, Dem_IumprReadinessGroupType, Dem_DTRControlType, Dem_DTCSeverityType, Dem_MonitorStatusType]
      timing event Timer_Dem_MasterMainFunction: start-on-event=Dem_MasterMainFunction, period=0.005
      19 x operation invoked event:
        OpEventPostRunRequested_GetPostRunRequested_DemServices: start-on-event=PostRunRequested, operation=DemServices.GetPostRunRequested
        OpEventGetDTCStatusAvailabilityMask_GetDTCStatusAvailabilityMask_DemServices: start-on-event=GetDTCStatusAvailabilityMask, operation=DemServices.GetDTCStatusAvailabilityMask
        OpEventGetEventUdsStatus_GetEventUdsStatus_GeneralEvtInfo: start-on-event=DemMaster_0InternalBehavior/GetEventUdsStatus, operation=GeneralEvtInfo.GetEventUdsStatus
        OpEventGetEventStatus_GetEventStatus_GeneralEvtInfo: start-on-event=DemMaster_0InternalBehavior/GetEventStatus, operation=GeneralEvtInfo.GetEventStatus
        OpEventGetEventFailed_GetEventFailed_GeneralEvtInfo: start-on-event=DemMaster_0InternalBehavior/GetEventFailed, operation=GeneralEvtInfo.GetEventFailed
        OpEventGetEventTested_GetEventTested_GeneralEvtInfo: start-on-event=DemMaster_0InternalBehavior/GetEventTested, operation=GeneralEvtInfo.GetEventTested
        OpEventGetDTCOfEvent_GetDTCOfEvent_GeneralEvtInfo: start-on-event=DemMaster_0InternalBehavior/GetDTCOfEvent, operation=GeneralEvtInfo.GetDTCOfEvent
        OpEventGetFaultDetectionCounter_GetFaultDetectionCounter_GeneralEvtInfo: start-on-event=DemMaster_0InternalBehavior/GetFaultDetectionCounter, operation=GeneralEvtInfo.GetFaultDetectionCounter
        OpEventGetEventFreezeFrameDataEx_GetEventFreezeFrameDataEx_GeneralEvtInfo: start-on-event=DemMaster_0InternalBehavior/GetEventFreezeFrameDataEx, operation=GeneralEvtInfo.GetEventFreezeFrameDataEx
        OpEventGetEventExtendedDataRecordEx_GetEventExtendedDataRecordEx_GeneralEvtInfo: start-on-event=DemMaster_0InternalBehavior/GetEventExtendedDataRecordEx, operation=GeneralEvtInfo.GetEventExtendedDataRecordEx
        OpEventGetEventEnableCondition_GetEventEnableCondition_GeneralEvtInfo: start-on-event=DemMaster_0InternalBehavior/GetEventEnableCondition, operation=GeneralEvtInfo.GetEventEnableCondition
        OpEventGetDebouncingOfEvent_GetDebouncingOfEvent_GeneralEvtInfo: start-on-event=DemMaster_0InternalBehavior/GetDebouncingOfEvent, operation=GeneralEvtInfo.GetDebouncingOfEvent
        OpEventGetMonitorStatus_GetMonitorStatus_GeneralEvtInfo: start-on-event=DemMaster_0InternalBehavior/GetMonitorStatus, operation=GeneralEvtInfo.GetMonitorStatus
        OpEventGetOperationCycleState_GetOperationCycleState_OpCycle_PowerCycle: start-on-event=GetOperationCycleState, operation=OpCycle_PowerCycle.GetOperationCycleState
        OpEventSetOperationCycleState_SetOperationCycleState_OpCycle_PowerCycle: start-on-event=SetOperationCycleState, operation=OpCycle_PowerCycle.SetOperationCycleState
        OpEventClearDTC_ClearDTC_ClearDTC_DemClient: start-on-event=ClearDTC, operation=ClearDTC_DemClient.ClearDTC
        OpEventSelectDTC_SelectDTC_ClearDTC_DemClient: start-on-event=SelectDTC, operation=ClearDTC_DemClient.SelectDTC
        OpEventGetEventMemoryOverflow_GetEventMemoryOverflow_OverflowIndPrimaryMemory_DemClient: start-on-event=GetEventMemoryOverflow, operation=OverflowIndPrimaryMemory_DemClient.GetEventMemoryOverflow
        OpEventGetNumberOfEventMemoryEntries_GetNumberOfEventMemoryEntries_OverflowIndPrimaryMemory_DemClient: start-on-event=GetNumberOfEventMemoryEntries, operation=OverflowIndPrimaryMemory_DemClient.GetNumberOfEventMemoryEntries
      port-api-options:
        enable-take-address=true, indirect-api=false, port=DemServices
        enable-take-address=true, indirect-api=false, port=CBFaultDetectCtr_DTC_0x402011
        enable-take-address=true, indirect-api=false, port=DemMaster_0/GeneralEvtInfo
        {enable-take-address=true, indirect-api=false, port-defined-argument-value{value=0, value-type=uint8}, port=OpCycle_PowerCycle}
        {enable-take-address=true, indirect-api=false, port-defined-argument-value{value=0, value-type=uint8}, port=ClearDTC_DemClient}
        {enable-take-address=true, indirect-api=false, port-arg-values=[{value=0, value-type=uint8}, {value=1, value-type=Dem_DTCOriginType}], port=OverflowIndPrimaryMemory_DemClient}
        enable-take-address=true, indirect-api=false, port=CBFaultDetectCtr_DTC_0x403413
        enable-take-address=true, indirect-api=false, port=CBFaultDetectCtr_DTC_0x404428
        enable-take-address=true, indirect-api=false, port=CBFaultDetectCtr_DTC_0x406321
        enable-take-address=true, indirect-api=false, port=CBFaultDetectCtr_DTC_0x406325
        enable-take-address=true, indirect-api=false, port=CBFaultDetectCtr_DTC_0x404421
        enable-take-address=true, indirect-api=false, port=CBFaultDetectCtr_DTC_0x404422
        enable-take-address=true, indirect-api=false, port=CBFaultDetectCtr_DTC_0x406322
        enable-take-address=true, indirect-api=false, port=CBFaultDetectCtr_DTC_0x403a21
        enable-take-address=true, indirect-api=false, port=CBFaultDetectCtr_DTC_0x403a22
        enable-take-address=true, indirect-api=false, port=CBFaultDetectCtr_DTC_0x403422
        enable-take-address=true, indirect-api=false, port=CBFaultDetectCtr_DTC_0x403421
        enable-take-address=true, indirect-api=false, port=CBFaultDetectCtr_DTC_0x402013
        enable-take-address=true, indirect-api=false, port=CBFaultDetectCtr_DTC_0x402012
        enable-take-address=true, indirect-api=false, port=CBFaultDetectCtr_DTC_0x402025
        enable-take-address=true, indirect-api=false, port=CBFaultDetectCtr_DTC_0x403713
        enable-take-address=true, indirect-api=false, port=CBFaultDetectCtr_DTC_0x406222
        enable-take-address=true, indirect-api=false, port=CBFaultDetectCtr_DTC_0x406221
        enable-take-address=true, indirect-api=false, port=CBFaultDetectCtr_DTC_0x406225
        enable-take-address=true, indirect-api=false, port=CBFaultDetectCtr_DTC_0x403113
        enable-take-address=true, indirect-api=false, port=CBFaultDetectCtr_DTC_0x403721
        enable-take-address=true, indirect-api=false, port=CBFaultDetectCtr_DTC_0x403722
        enable-take-address=true, indirect-api=false, port=CBFaultDetectCtr_DTC_0x404011
        enable-take-address=true, indirect-api=false, port=CBFaultDetectCtr_DTC_0x404212
        enable-take-address=true, indirect-api=false, port=CBFaultDetectCtr_DTC_0x404213
        enable-take-address=true, indirect-api=false, port=CBFaultDetectCtr_DTC_0x404012
        enable-take-address=true, indirect-api=false, port=CBFaultDetectCtr_DTC_0x403121
        enable-take-address=true, indirect-api=false, port=CBFaultDetectCtr_DTC_0x404211
        enable-take-address=true, indirect-api=false, port=CBFaultDetectCtr_DTC_0x404013
        enable-take-address=true, indirect-api=false, port=CBFaultDetectCtr_DTC_0x403122
        enable-take-address=true, indirect-api=false, port=CBFaultDetectCtr_DTC_0x403a13
        enable-take-address=true, indirect-api=false, port=DemMaster_0/CBReadData_UncompletedTestCounters_Driving_Cycles_Since_Last_Completed
        enable-take-address=true, indirect-api=false, port=DemMaster_0/CBReadData_DID_0x10d_Valve_Voltage_RL
        enable-take-address=true, indirect-api=false, port=DemMaster_0/CBReadData_DID_0x10a_Wheel_Voltage_RL
        enable-take-address=true, indirect-api=false, port=DemMaster_0/CBReadData_DID_0x107_Voltage_ECU
        enable-take-address=true, indirect-api=false, port=DemMaster_0/CBReadData_DID_0x10d_Valve_Voltage_RR
        enable-take-address=true, indirect-api=false, port=DemMaster_0/CBReadData_DTCAgingCounter_Driving_Cycles_Since_Last_Failed
        enable-take-address=true, indirect-api=false, port=DemMaster_0/CBReadData_DID_0x10d_Valve_Status_FR
        enable-take-address=true, indirect-api=false, port=DemMaster_0/CBReadData_DID_0x10a_Wheel_Voltage_RR
        enable-take-address=true, indirect-api=false, port=DemMaster_0/CBReadData_DID_0x10a_Wheel_Voltage_FR
        enable-take-address=true, indirect-api=false, port=DemMaster_0/CBReadData_DID_0x10a_Wheel_Voltage_FL
        enable-take-address=true, indirect-api=false, port=DemMaster_0/CBReadData_DID_0x10d_Valve_Status_RR
        enable-take-address=true, indirect-api=false, port=DemMaster_0/CBReadData_DID_0x10a_Wheel_Speed_RL
        enable-take-address=true, indirect-api=false, port=DemMaster_0/CBReadData_DID_0x10a_Wheel_Speed_RR
        enable-take-address=true, indirect-api=false, port=DemMaster_0/CBReadData_DID_0x10a_Wheel_Speed_FL
        enable-take-address=true, indirect-api=false, port=DemMaster_0/CBReadData_DID_0x10d_Valve_Status_FL
        enable-take-address=true, indirect-api=false, port=DemMaster_0/CBReadData_DID_0x10a_Direction_of_rotation
        enable-take-address=true, indirect-api=false, port=DemMaster_0/CBReadData_DID_0x10d_Valve_Voltage_FL
        enable-take-address=true, indirect-api=false, port=DemMaster_0/CBReadData_DID_0x10a_Wheel_Speed_FR
        enable-take-address=true, indirect-api=false, port=DemMaster_0/CBReadData_DID_0x10d_Valve_Voltage_FR
        enable-take-address=true, indirect-api=false, port=DemMaster_0/CBReadData_OccurrenceCounter_Driving_Cycles_Since_Test_Failed
        enable-take-address=true, indirect-api=false, port=DemMaster_0/CBReadData_DID_0x10d_Valve_Status_RL
        enable-take-address=true, indirect-api=false, port=CBFaultDetectCtr_DTC_0x401003
        enable-take-address=true, indirect-api=false, port=CBFaultDetectCtr_DTC_0x401001
        enable-take-address=true, indirect-api=false, port=CBFaultDetectCtr_DTC_0x402001
        enable-take-address=true, indirect-api=false, port=CBFaultDetectCtr_DTC_0x403001
      20 x runnable:
        Dem_MasterMainFunction
          56 x sync call, all with timeout=0:
            OpServerCallDem_MasterMainFunction_GetFaultDetectionCounter_CBFaultDetectCtr_DTC_0x402011: operation=CBFaultDetectCtr_DTC_0x402011.GetFaultDetectionCounter
            OpServerCallDem_MasterMainFunction_GetFaultDetectionCounter_CBFaultDetectCtr_DTC_0x403413: operation=CBFaultDetectCtr_DTC_0x403413.GetFaultDetectionCounter
            OpServerCallDem_MasterMainFunction_GetFaultDetectionCounter_CBFaultDetectCtr_DTC_0x404428: operation=CBFaultDetectCtr_DTC_0x404428.GetFaultDetectionCounter
            OpServerCallDem_MasterMainFunction_GetFaultDetectionCounter_CBFaultDetectCtr_DTC_0x406321: operation=CBFaultDetectCtr_DTC_0x406321.GetFaultDetectionCounter
            OpServerCallDem_MasterMainFunction_GetFaultDetectionCounter_CBFaultDetectCtr_DTC_0x406325: operation=CBFaultDetectCtr_DTC_0x406325.GetFaultDetectionCounter
            OpServerCallDem_MasterMainFunction_GetFaultDetectionCounter_CBFaultDetectCtr_DTC_0x404421: operation=CBFaultDetectCtr_DTC_0x404421.GetFaultDetectionCounter
            OpServerCallDem_MasterMainFunction_GetFaultDetectionCounter_CBFaultDetectCtr_DTC_0x404422: operation=CBFaultDetectCtr_DTC_0x404422.GetFaultDetectionCounter
            OpServerCallDem_MasterMainFunction_GetFaultDetectionCounter_CBFaultDetectCtr_DTC_0x406322: operation=CBFaultDetectCtr_DTC_0x406322.GetFaultDetectionCounter
            OpServerCallDem_MasterMainFunction_GetFaultDetectionCounter_CBFaultDetectCtr_DTC_0x403a21: operation=CBFaultDetectCtr_DTC_0x403a21.GetFaultDetectionCounter
            OpServerCallDem_MasterMainFunction_GetFaultDetectionCounter_CBFaultDetectCtr_DTC_0x403a22: operation=CBFaultDetectCtr_DTC_0x403a22.GetFaultDetectionCounter
            OpServerCallDem_MasterMainFunction_GetFaultDetectionCounter_CBFaultDetectCtr_DTC_0x403422: operation=CBFaultDetectCtr_DTC_0x403422.GetFaultDetectionCounter
            OpServerCallDem_MasterMainFunction_GetFaultDetectionCounter_CBFaultDetectCtr_DTC_0x403421: operation=CBFaultDetectCtr_DTC_0x403421.GetFaultDetectionCounter
            OpServerCallDem_MasterMainFunction_GetFaultDetectionCounter_CBFaultDetectCtr_DTC_0x402013: operation=CBFaultDetectCtr_DTC_0x402013.GetFaultDetectionCounter
            OpServerCallDem_MasterMainFunction_GetFaultDetectionCounter_CBFaultDetectCtr_DTC_0x402012: operation=CBFaultDetectCtr_DTC_0x402012.GetFaultDetectionCounter
            OpServerCallDem_MasterMainFunction_GetFaultDetectionCounter_CBFaultDetectCtr_DTC_0x402025: operation=CBFaultDetectCtr_DTC_0x402025.GetFaultDetectionCounter
            OpServerCallDem_MasterMainFunction_GetFaultDetectionCounter_CBFaultDetectCtr_DTC_0x403713: operation=CBFaultDetectCtr_DTC_0x403713.GetFaultDetectionCounter
            OpServerCallDem_MasterMainFunction_GetFaultDetectionCounter_CBFaultDetectCtr_DTC_0x406222: operation=CBFaultDetectCtr_DTC_0x406222.GetFaultDetectionCounter
            OpServerCallDem_MasterMainFunction_GetFaultDetectionCounter_CBFaultDetectCtr_DTC_0x406221: operation=CBFaultDetectCtr_DTC_0x406221.GetFaultDetectionCounter
            OpServerCallDem_MasterMainFunction_GetFaultDetectionCounter_CBFaultDetectCtr_DTC_0x406225: operation=CBFaultDetectCtr_DTC_0x406225.GetFaultDetectionCounter
            OpServerCallDem_MasterMainFunction_GetFaultDetectionCounter_CBFaultDetectCtr_DTC_0x403113: operation=CBFaultDetectCtr_DTC_0x403113.GetFaultDetectionCounter
            OpServerCallDem_MasterMainFunction_GetFaultDetectionCounter_CBFaultDetectCtr_DTC_0x403721: operation=CBFaultDetectCtr_DTC_0x403721.GetFaultDetectionCounter
            OpServerCallDem_MasterMainFunction_GetFaultDetectionCounter_CBFaultDetectCtr_DTC_0x403722: operation=CBFaultDetectCtr_DTC_0x403722.GetFaultDetectionCounter
            OpServerCallDem_MasterMainFunction_GetFaultDetectionCounter_CBFaultDetectCtr_DTC_0x404011: operation=CBFaultDetectCtr_DTC_0x404011.GetFaultDetectionCounter
            OpServerCallDem_MasterMainFunction_GetFaultDetectionCounter_CBFaultDetectCtr_DTC_0x404212: operation=CBFaultDetectCtr_DTC_0x404212.GetFaultDetectionCounter
            OpServerCallDem_MasterMainFunction_GetFaultDetectionCounter_CBFaultDetectCtr_DTC_0x404213: operation=CBFaultDetectCtr_DTC_0x404213.GetFaultDetectionCounter
            OpServerCallDem_MasterMainFunction_GetFaultDetectionCounter_CBFaultDetectCtr_DTC_0x404012: operation=CBFaultDetectCtr_DTC_0x404012.GetFaultDetectionCounter
            OpServerCallDem_MasterMainFunction_GetFaultDetectionCounter_CBFaultDetectCtr_DTC_0x403121: operation=CBFaultDetectCtr_DTC_0x403121.GetFaultDetectionCounter
            OpServerCallDem_MasterMainFunction_GetFaultDetectionCounter_CBFaultDetectCtr_DTC_0x404211: operation=CBFaultDetectCtr_DTC_0x404211.GetFaultDetectionCounter
            OpServerCallDem_MasterMainFunction_GetFaultDetectionCounter_CBFaultDetectCtr_DTC_0x404013: operation=CBFaultDetectCtr_DTC_0x404013.GetFaultDetectionCounter
            OpServerCallDem_MasterMainFunction_GetFaultDetectionCounter_CBFaultDetectCtr_DTC_0x403122: operation=CBFaultDetectCtr_DTC_0x403122.GetFaultDetectionCounter
            OpServerCallDem_MasterMainFunction_GetFaultDetectionCounter_CBFaultDetectCtr_DTC_0x403a13: operation=CBFaultDetectCtr_DTC_0x403a13.GetFaultDetectionCounter
            OpServerCallDem_MasterMainFunction_ReadData_CBReadData_UncompletedTestCounters_Driving_Cycles_Since_Last_Completed: operation=CBReadData_UncompletedTestCounters_Driving_Cycles_Since_Last_Completed.ReadData
            OpServerCallDem_MasterMainFunction_ReadData_CBReadData_DID_0x10d_Valve_Voltage_RL: operation=CBReadData_DID_0x10d_Valve_Voltage_RL.ReadData
            OpServerCallDem_MasterMainFunction_ReadData_CBReadData_DID_0x10a_Wheel_Voltage_RL: operation=CBReadData_DID_0x10a_Wheel_Voltage_RL.ReadData
            OpServerCallDem_MasterMainFunction_ReadData_CBReadData_DID_0x107_Voltage_ECU: operation=CBReadData_DID_0x107_Voltage_ECU.ReadData
            OpServerCallDem_MasterMainFunction_ReadData_CBReadData_DID_0x10d_Valve_Voltage_RR: operation=CBReadData_DID_0x10d_Valve_Voltage_RR.ReadData
            OpServerCallDem_MasterMainFunction_ReadData_CBReadData_DTCAgingCounter_Driving_Cycles_Since_Last_Failed: operation=CBReadData_DTCAgingCounter_Driving_Cycles_Since_Last_Failed.ReadData
            OpServerCallDem_MasterMainFunction_ReadData_CBReadData_DID_0x10d_Valve_Status_FR: operation=CBReadData_DID_0x10d_Valve_Status_FR.ReadData
            OpServerCallDem_MasterMainFunction_ReadData_CBReadData_DID_0x10a_Wheel_Voltage_RR: operation=CBReadData_DID_0x10a_Wheel_Voltage_RR.ReadData
            OpServerCallDem_MasterMainFunction_ReadData_CBReadData_DID_0x10a_Wheel_Voltage_FR: operation=CBReadData_DID_0x10a_Wheel_Voltage_FR.ReadData
            OpServerCallDem_MasterMainFunction_ReadData_CBReadData_DID_0x10a_Wheel_Voltage_FL: operation=CBReadData_DID_0x10a_Wheel_Voltage_FL.ReadData
            OpServerCallDem_MasterMainFunction_ReadData_CBReadData_DID_0x10d_Valve_Status_RR: operation=CBReadData_DID_0x10d_Valve_Status_RR.ReadData
            OpServerCallDem_MasterMainFunction_ReadData_CBReadData_DID_0x10a_Wheel_Speed_RL: operation=CBReadData_DID_0x10a_Wheel_Speed_RL.ReadData
            OpServerCallDem_MasterMainFunction_ReadData_CBReadData_DID_0x10a_Wheel_Speed_RR: operation=CBReadData_DID_0x10a_Wheel_Speed_RR.ReadData
            OpServerCallDem_MasterMainFunction_ReadData_CBReadData_DID_0x10a_Wheel_Speed_FL: operation=CBReadData_DID_0x10a_Wheel_Speed_FL.ReadData
            OpServerCallDem_MasterMainFunction_ReadData_CBReadData_DID_0x10d_Valve_Status_FL: operation=CBReadData_DID_0x10d_Valve_Status_FL.ReadData
            OpServerCallDem_MasterMainFunction_ReadData_CBReadData_DID_0x10a_Direction_of_rotation: operation=CBReadData_DID_0x10a_Direction_of_rotation.ReadData
            OpServerCallDem_MasterMainFunction_ReadData_CBReadData_DID_0x10d_Valve_Voltage_FL: operation=CBReadData_DID_0x10d_Valve_Voltage_FL.ReadData
            OpServerCallDem_MasterMainFunction_ReadData_CBReadData_DID_0x10a_Wheel_Speed_FR: operation=CBReadData_DID_0x10a_Wheel_Speed_FR.ReadData
            OpServerCallDem_MasterMainFunction_ReadData_CBReadData_DID_0x10d_Valve_Voltage_FR: operation=CBReadData_DID_0x10d_Valve_Voltage_FR.ReadData
            OpServerCallDem_MasterMainFunction_ReadData_CBReadData_OccurrenceCounter_Driving_Cycles_Since_Test_Failed: operation=CBReadData_OccurrenceCounter_Driving_Cycles_Since_Test_Failed.ReadData
            OpServerCallDem_MasterMainFunction_ReadData_CBReadData_DID_0x10d_Valve_Status_RL: operation=CBReadData_DID_0x10d_Valve_Status_RL.ReadData
            OpServerCallDem_MasterMainFunction_GetFaultDetectionCounter_CBFaultDetectCtr_DTC_0x401003: operation=CBFaultDetectCtr_DTC_0x401003.GetFaultDetectionCounter
            OpServerCallDem_MasterMainFunction_GetFaultDetectionCounter_CBFaultDetectCtr_DTC_0x401001: operation=CBFaultDetectCtr_DTC_0x401001.GetFaultDetectionCounter
            OpServerCallDem_MasterMainFunction_GetFaultDetectionCounter_CBFaultDetectCtr_DTC_0x402001: operation=CBFaultDetectCtr_DTC_0x402001.GetFaultDetectionCounter
            OpServerCallDem_MasterMainFunction_GetFaultDetectionCounter_CBFaultDetectCtr_DTC_0x403001: operation=CBFaultDetectCtr_DTC_0x403001.GetFaultDetectionCounter
        PostRunRequested: can-be-invoked-concurrently=true, symbol=Dem_PostRunRequested
        GetDTCStatusAvailabilityMask: can-be-invoked-concurrently=true, symbol=Dem_GetDTCStatusAvailabilityMask
        GetEventUdsStatus: can-be-invoked-concurrently=true, symbol=Dem_GetEventUdsStatus
        GetEventStatus: can-be-invoked-concurrently=true, symbol=Dem_GetEventUdsStatus
        GetEventFailed: can-be-invoked-concurrently=true, symbol=Dem_GetEventFailed
        GetEventTested: can-be-invoked-concurrently=true, symbol=Dem_GetEventTested
        GetDTCOfEvent: can-be-invoked-concurrently=true, symbol=Dem_GetDTCOfEvent
        GetFaultDetectionCounter: can-be-invoked-concurrently=true, symbol=Dem_GetFaultDetectionCounter
        GetEventFreezeFrameDataEx: can-be-invoked-concurrently=true, symbol=Dem_GetEventFreezeFrameDataEx
        GetEventExtendedDataRecordEx: can-be-invoked-concurrently=true, symbol=Dem_GetEventExtendedDataRecordEx
        GetEventEnableCondition: can-be-invoked-concurrently=true, symbol=Dem_GetEventEnableCondition
        GetDebouncingOfEvent: can-be-invoked-concurrently=true, symbol=Dem_GetDebouncingOfEvent
        GetMonitorStatus: can-be-invoked-concurrently=true, symbol=Dem_GetMonitorStatus
        GetOperationCycleState: can-be-invoked-concurrently=true, symbol=Dem_GetOperationCycleState
        SetOperationCycleState: can-be-invoked-concurrently=true, symbol=Dem_SetOperationCycleState
        ClearDTC: can-be-invoked-concurrently=true, symbol=Dem_ClearDTC
        SelectDTC: can-be-invoked-concurrently=true, symbol=Dem_SelectDTC
        GetEventMemoryOverflow: can-be-invoked-concurrently=true, symbol=Dem_GetEventMemoryOverflow
        GetNumberOfEventMemoryEntries: can-be-invoked-concurrently=true, symbol=Dem_GetNumberOfEventMemoryEntries
  swc implementation DemMaster_0Implementation: programming-language=C, behavior=DemMaster_0InternalBehavior
